# nRF7140_graphics register map
Vendor: Nordic Semiconductor; Series: nRF71; File version: 1
CPU: CM33 r0p4, little endian, MPU, FPU, 3 interrupt priority bits, 480 interrupts
Registers are 32-bit, read-write, reset 0x0 unless marked. A register's access mark holds for its fields unless they carry their own. Offsets are from the block's base; [hi:lo] are bit positions; lines under a group give offsets from that group; {n}, {i} and the like mark numbered series; 'fields as' and 'values as' point back to an identical list.

## GLOBAL_DPPIC110_NS — Distributed programmable peripheral interconnect controller 0
Base 0x4F0A6000
Same registers: GLOBAL_DPPIC120_NS 0x4F8E1000, GLOBAL_DPPIC130_NS 0x4F922000, GLOBAL_DPPIC131_NS 0x4F981000, GLOBAL_DPPIC132_NS 0x4F991000, GLOBAL_DPPIC133_NS 0x4F9A1000, GLOBAL_DPPIC134_NS 0x4F9B1000, GLOBAL_DPPIC135_NS 0x4F9C1000, GLOBAL_DPPIC136_NS 0x4F9D1000, GLOBAL_DPPIC110_S 0x5F0A6000, GLOBAL_DPPIC120_S 0x5F8E1000, GLOBAL_DPPIC130_S 0x5F922000, GLOBAL_DPPIC131_S 0x5F981000, GLOBAL_DPPIC132_S 0x5F991000, GLOBAL_DPPIC133_S 0x5F9A1000, GLOBAL_DPPIC134_S 0x5F9B1000, GLOBAL_DPPIC135_S 0x5F9C1000, GLOBAL_DPPIC136_S 0x5F9D1000
{0x0+8i} TASKS_CHG[{i}] (i=0..3) group — Channel group tasks
  0x00 EN wo — Description cluster: Enable channel group n
    [0] EN — Enable channel group n
      1=Trigger task
  0x04 DIS wo — Description cluster: Disable channel group n
    [0] DIS — Disable channel group n
      1=Trigger task
{0x80+8i} SUBSCRIBE_CHG[{i}] (i=0..3) group — Subscribe configuration for tasks
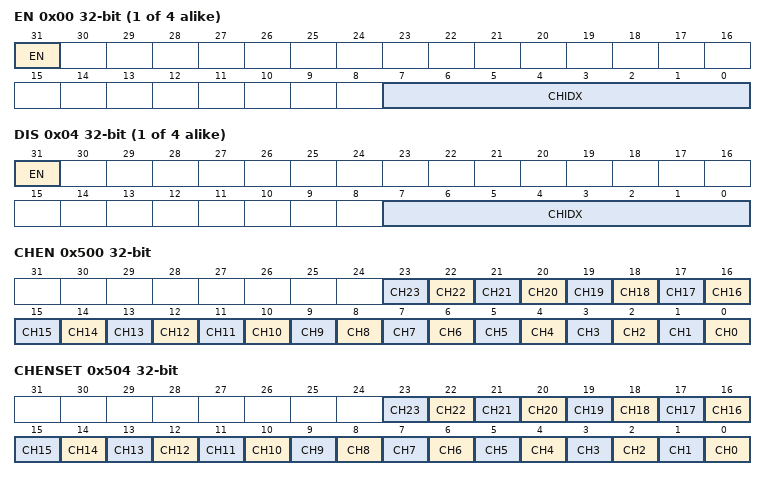
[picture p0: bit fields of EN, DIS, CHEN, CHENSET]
  0x00 EN — Description cluster: Subscribe configuration for task CHG[n].EN
    [31] EN
      0=Disabled (Disable subscription); 1=Enabled (Enable subscription)
    [7:0] CHIDX — DPPI channel that task CHG[n].EN will subscribe to
  0x04 DIS — Description cluster: Subscribe configuration for task CHG[n].DIS
    [31] EN
      values as SUBSCRIBE_CHG[0].EN.EN
    [7:0] CHIDX — DPPI channel that task CHG[n].DIS will subscribe to
0x500 CHEN — Channel enable register
  [all] fields
    0=Disabled (Disable channel); 1=Enabled (Enable channel)
  [n] CH{n} (n=0..23) — Enable or disable channel {n}
0x504 CHENSET write-1-sets — Channel enable set register
  [all] fields
    on read: 0=Disabled (Read: Channel disabled); 1=Enabled (Read: Channel enabled) | on write: 1=Set (Write: Enable channel)
  [n] CH{n} (n=0..23) — Channel {n} enable set register. Writing 0 has no effect.
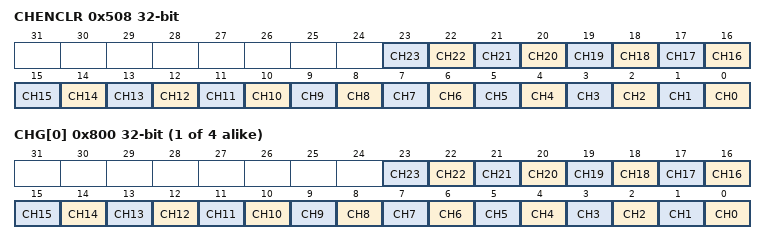
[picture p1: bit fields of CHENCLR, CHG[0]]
0x508 CHENCLR write-1-clears — Channel enable clear register
  [all] fields
    on read: 0=Disabled (Read: Channel disabled); 1=Enabled (Read: Channel enabled) | on write: 1=Clear (Write: Disable channel)
  [n] CH{n} (n=0..23) — Channel {n} enable clear register. Writing 0 has no effect.
{0x800+4i} CHG[{i}] (i=0..3) — Description collection: Channel group n Note: Writes to this register are ignored if either SUBSCRIBE_CHG[n].EN or SUBSCRIBE_CHG[n].DIS is enabled
  [all] fields
    0=Excluded; 1=Included
  [n] CH{n} (n=0..23) — Include or exclude channel {n}

## GLOBAL_CANPLLPM_S — AUXPM
Base 0x5F8C2000
0x20 TASKS_START wo — Request power up
  [0] TASKS_START
    1=Trigger task
0x24 TASKS_STOP wo — Stop requesting power up
  [0] TASKS_STOP
    1=Trigger task
0x110 EVENTS_SETTLED — LDO settled
  [0] EVENTS_SETTLED
    0=NotGenerated (Event not generated); 1=Generated (Event generated)
0x300 INTEN — Enable or disable interrupt
  [4] SETTLED — Enable or disable interrupt for event SETTLED
    0=Disabled; 1=Enabled
0x304 INTENSET — Enable interrupt
  [4] SETTLED — Write '1' to enable interrupt for event SETTLED
    on read: 0=Disabled (Read: Disabled); 1=Enabled (Read: Enabled) | on write: 1=Set (Enable)
0x308 INTENCLR — Disable interrupt
  [4] SETTLED — Write '1' to disable interrupt for event SETTLED
    on read: 0=Disabled (Read: Disabled); 1=Enabled (Read: Enabled) | on write: 1=Clear (Disable)
0x30C INTPEND ro — Pending interrupts
  [4] SETTLED — Read pending status of interrupt for event SETTLED
    on read: 0=NotPending (Read: Not pending); 1=Pending (Read: Pending)
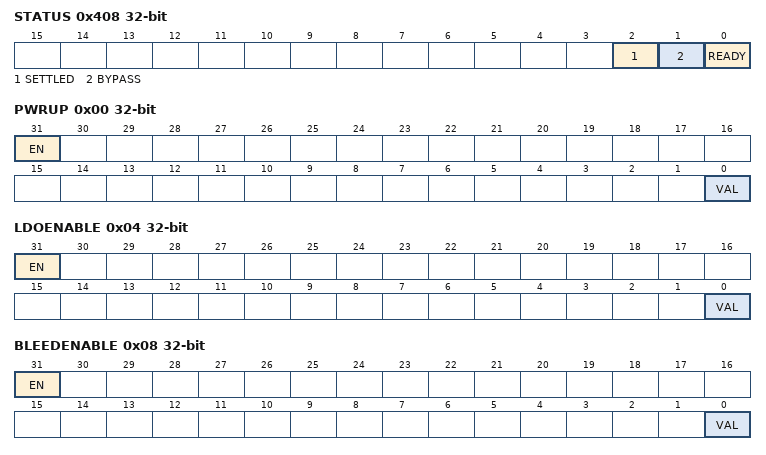
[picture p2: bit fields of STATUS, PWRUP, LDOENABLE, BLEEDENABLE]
0x408 STATUS ro — Status of AuxPm
  [2] SETTLED — LDO settled
    0=NotSettled (AuxPm not settled); 1=Settled (AuxPm settled)
  [1] BYPASS — Bypassing vref filter for startup boost
    0=NotBypass (VrefFilt not bypassed); 1=Bypass (VrefFilt bypassed)
  [0] READY — AuxPm powered up
    0=PowerDown (AuxPm powered down); 1=Powered (AuxPm powered up)
0x420 CONFIG group — Unspecified
  0x00 STARTUPTIME reset 0x18 — Time from pwrup to ready signal (0us-3us)
    [5:0] VAL — Timer value
      0=Min (0 us); 24=Default (1.5 us); 48=Max (3 us)
  0x04 SHUTDOWNTIME reset 0x18 — Time from shutdown until to ready signal is deasserted (0us-3us)
    fields as CONFIG.STARTUPTIME
  0x08 BYPASSTIME reset 0x70 — Time from ready until bypass vref turned off (7us-40us)
    [9:0] VAL — Timer value
      112=Min (7 us); 112=Default (7 us); 0x280=Max (40 us)
  0x0C SETLTIME reset 0x18 — Time from bypass turned off to settled (0us-3us)
    fields as CONFIG.STARTUPTIME
0x450 TRIM group — Unspecified
  0x00 VREFPM — Reference voltage trimming. Equals output voltage
    [2:0] VAL — Voltage trimming value.
      0=Val800mV (800 mV); 1=Val825mV (825 mV); 2=Val850mV (850 mV); 3=Val900mV (900 mV); 4=Val600mV (600 mV); 5=Val650mV (650 mV); 6=Val700mV (700 mV); 7=Val750mV (750 mV)
0x4F0 MIRROR — Enable LOCK for mirrored registers
  [0] LOCK — Lock for mirrored registers
    0=Disabled (Lock disabled); 1=Enabled (Lock enabled)
0x580 OVERRIDE group — Unspecified
  0x00 PWRUP — Override the pwrup to the analog module
    [31] EN — Enable the override
      0=Disabled (Override is disabled); 1=Enabled (Override is enabled)
    [0] VAL — Override value for the signal
  0x04 LDOENABLE — Override the LDO enable to the analog module
    fields as OVERRIDE.PWRUP
  0x08 BLEEDENABLE — Override the bleed enable to the analog module
    fields as OVERRIDE.PWRUP
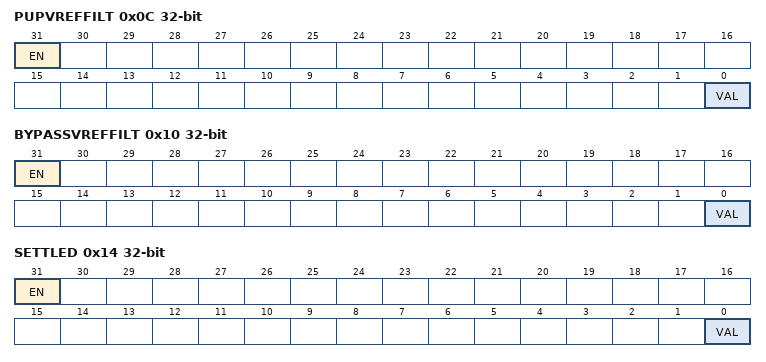
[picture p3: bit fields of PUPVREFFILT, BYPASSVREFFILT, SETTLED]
  0x0C PUPVREFFILT — Override the vref filter enable to the analog module
    fields as OVERRIDE.PWRUP
  0x10 BYPASSVREFFILT — Override the vref bypass to the analog module
    fields as OVERRIDE.PWRUP
  0x14 SETTLED — Override the SETTLED from the digital part
    fields as OVERRIDE.PWRUP
0x680 DFT group — Unspecified
  0x00 ATB0CONFIG — Analog Test Bus 0 (ATB0) configuration
    [31] EN
      0=Disabled (Analog test bus is disabled); 1=Enabled (Analog test bus is enabled)
  0x04 ATB1CONFIG — Analog Test Bus 1 (ATB1) configuration
    fields as DFT.ATB0CONFIG
